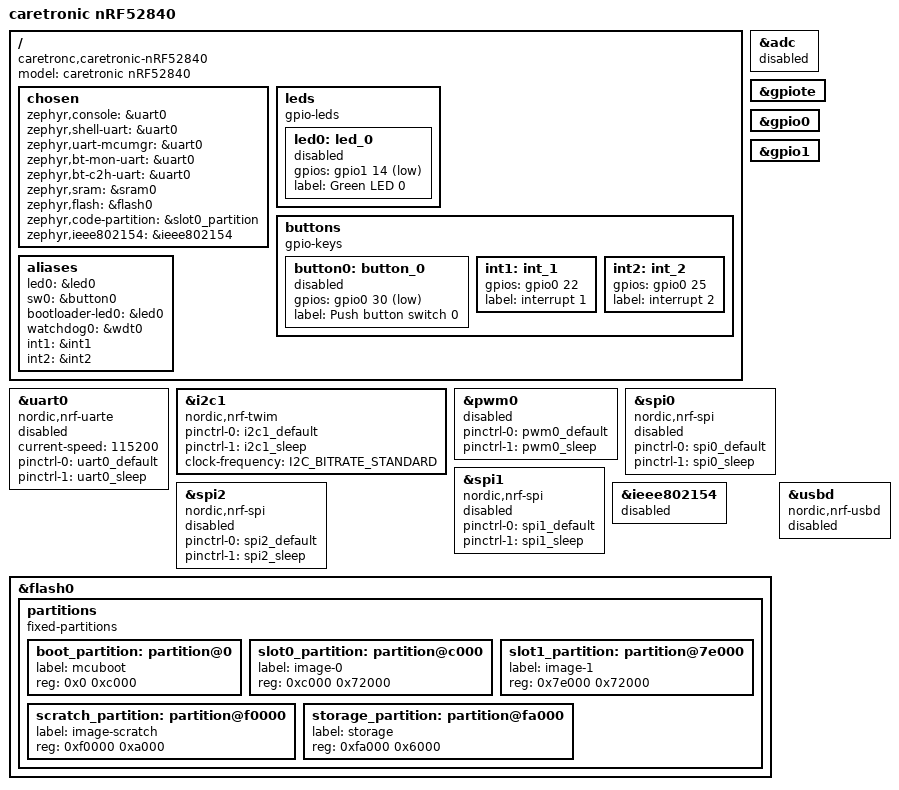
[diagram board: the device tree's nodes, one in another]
/*
 * Copyright (c) 2017 Linaro Limited
 *
 * SPDX-License-Identifier: Apache-2.0
 */

/dts-v1/;
#include <nordic/nrf52840_qiaa.dtsi>
#include "caretronic_nrf52840-pinctrl.dtsi"

/ {
	model = "caretronic nRF52840";
	compatible = "caretronc,caretronic-nRF52840";

	chosen {
		zephyr,console = &uart0;
		zephyr,shell-uart = &uart0;
		zephyr,uart-mcumgr = &uart0;
		zephyr,bt-mon-uart = &uart0;
		zephyr,bt-c2h-uart = &uart0;
		zephyr,sram = &sram0;
		zephyr,flash = &flash0;
		zephyr,code-partition = &slot0_partition;
		zephyr,ieee802154 = &ieee802154;
	};

	leds {
		compatible = "gpio-leds";
		led0: led_0 {
			status = "disabled";
			gpios = <&gpio1 14 GPIO_ACTIVE_LOW>;
			label = "Green LED 0";
		};
	};



	buttons {
		compatible = "gpio-keys";
		button0: button_0 {
			status = "disabled";
			gpios = <&gpio0 30 GPIO_ACTIVE_LOW>;
			label = "Push button switch 0";
		};
		int1: int_1 {
			status = "okay";
			gpios = <&gpio0 22 GPIO_ACTIVE_HIGH>;
			label = "interrupt 1";
		};
		int2: int_2 {
			status = "okay";
			gpios = <&gpio0 25 GPIO_ACTIVE_HIGH>;
			label = "interrupt 2";
		};
	};



	/* These aliases are provided for compatibility with samples */
	aliases {
		led0 = &led0;
		sw0 = &button0;
		bootloader-led0 = &led0;
		watchdog0 = &wdt0;
		int1= &int1;
		int2= &int2;
	};
};

&adc {
	status = "disabled";
};

&gpiote {
	status = "okay";
};

&gpio0 {
	status = "okay";

};

&gpio1 {
	status = "okay";
};

&uart0 {
	compatible = "nordic,nrf-uarte";
	status = "disabled";
	current-speed = <115200>;
	pinctrl-0 = <&uart0_default>;
	pinctrl-1 = <&uart0_sleep>;
	pinctrl-names = "default", "sleep";
};




&i2c1 {
	compatible = "nordic,nrf-twim";
	status = "okay";
	pinctrl-0 = <&i2c1_default>;
	pinctrl-1 = <&i2c1_sleep>;
	pinctrl-names = "default", "sleep";
	clock-frequency = <I2C_BITRATE_STANDARD>;
	//irq-gpios = <&gpio0 22 GPIO_ACTIVE_HIGH>, <&gpio0 25 GPIO_ACTIVE_HIGH>;

};


&pwm0 {
	status = "disabled";
	pinctrl-0 = <&pwm0_default>;
	pinctrl-1 = <&pwm0_sleep>;
	pinctrl-names = "default", "sleep";
};

&spi0 {
	compatible = "nordic,nrf-spi";
	/* Cannot be used together with i2c0. */
	status = "disabled";
	pinctrl-0 = <&spi0_default>;
	pinctrl-1 = <&spi0_sleep>;
	pinctrl-names = "default", "sleep";
};

&spi1 {
	compatible = "nordic,nrf-spi";
	status = "disabled";
	pinctrl-0 = <&spi1_default>;
	pinctrl-1 = <&spi1_sleep>;
	pinctrl-names = "default", "sleep";
};

&spi2 {
	compatible = "nordic,nrf-spi";
	status = "disabled";
	pinctrl-0 = <&spi2_default>;
	pinctrl-1 = <&spi2_sleep>;
	pinctrl-names = "default", "sleep";
};
&ieee802154 {
	status = "disabled";
};

&flash0 {
	partitions {
		compatible = "fixed-partitions";
		#address-cells = <1>;
		#size-cells = <1>;

		boot_partition: partition@0 {
			label = "mcuboot";
			reg = <0x0 0xc000>;
		};
		slot0_partition: partition@c000 {
			label = "image-0";
			reg = <0xc000 0x72000>;
		};
		slot1_partition: partition@7e000 {
			label = "image-1";
			reg = <0x7e000 0x72000>;
		};
		scratch_partition: partition@f0000 {
			label = "image-scratch";
			reg = <0xf0000 0xa000>;
		};
		storage_partition: partition@fa000 {
			label = "storage";
			reg = <0xfa000 0x6000>;
		};
	};
};



zephyr_udc0: &usbd {
	compatible = "nordic,nrf-usbd";
	status = "disabled";
};

